# allwinner_d1_unofficial register map
File version: 0.1
Registers are 32-bit, read-write, reset 0x0 unless marked. A register's access mark holds for its fields unless they carry their own. Offsets are from the block's base; [hi:lo] are bit positions; {n}, {i} and the like mark numbered series.

## CLINT — Core-Local Interruptor
Base 0x14000000
0x00 msip range 0..1 — MSIP Register for hart 0
0x4000 mtimecmpl — MTIMECMPL Register for hart 0
0x4004 mtimecmph — MTIMECMPH Register for hart 0
0xBFF8 mtime 64-bit ro (reset mask 0xFFFFFFFF) — MTIME . REF: opensbi
0xC000 ssip range 0..1 — SSIP Register for hart 0
0xD000 stimecmpl — STIMECMPL Register for hart 0
0xD004 stimecmph — STIMECMPH Register for hart 0

## TIMER — Timer Module, includes timer0, timer1, watchdog and audio video synchronization
Base 0x02050000
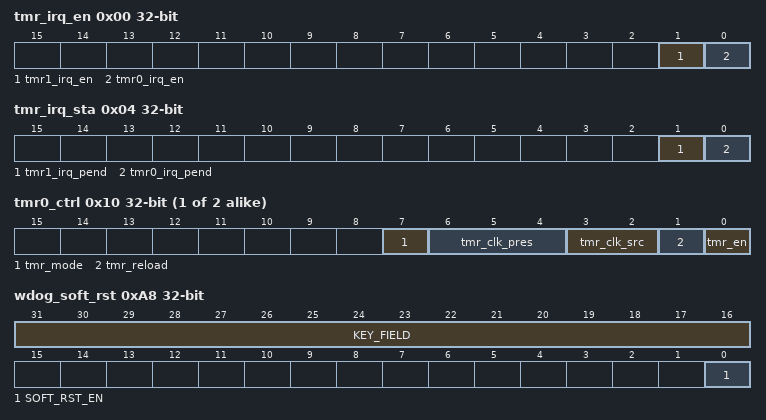
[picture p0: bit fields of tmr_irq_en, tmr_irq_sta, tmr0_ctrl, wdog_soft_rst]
0x00 tmr_irq_en — Timer IRQ Enable Register
  [1] tmr1_irq_en
    0=disabled; 1=enabled
  [0] tmr0_irq_en
    0=disabled; 1=enabled
0x04 tmr_irq_sta — Timer Status Register
  [1] tmr1_irq_pend
    0=no_effect; 1=pending (Indicates that the interval value of the timer 1 is reached. Write 1 to clear the pending status.)
  [0] tmr0_irq_pend
    0=no_effect; 1=pending (Indicates that the interval value of the timer 0 is reached. Write 1 to clear the pending status.)
{0x10+0x10*i} tmr{i}_ctrl (i=0..1) — Timer IRQ Enable Register
  [7] tmr_mode
    0=periodic; 1=single_counting
  [6:4] tmr_clk_pres
    0=P1; 1=P2; 2=P4; 3=P8; 4=P16; 5=P32; 6=P64; 7=P128
  [3:2] tmr_clk_src
    0=losc; 1=osc24_m
  [1] tmr_reload
    0=no_effect; 1=reload
  [0] tmr_en
    0=stop_pause; 1=start
{0x14+0x10*i} tmr{i}_intv_value (i=0..1) — Timer Interval Value Register
{0x18+0x10*i} tmr{i}_cur_value (i=0..1) — Timer Current Value Register
0xA0 wdog_irq_en — Watchdog IRQ Enable Register
  [0] wdog_irq_en
    0=disabled; 1=enabled
0xA4 wdog_irq_sta — Watchdog Status Register
  [0] wdog_irq_pend
    0=no_effect; 1=pending (Indicates that the interval value of the watchdog is reached.)
0xA8 wdog_soft_rst — Watchdog Software Reset Register
  [31:16] KEY_FIELD wo
  [0] SOFT_RST_EN — Soft Reset Enable
    0=Deassert; 1=Reset
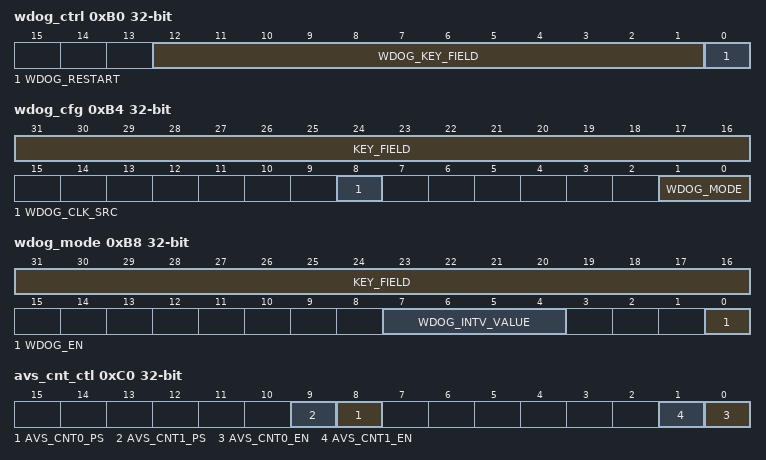
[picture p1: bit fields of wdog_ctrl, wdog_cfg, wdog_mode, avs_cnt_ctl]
0xB0 wdog_ctrl — Watchdog Control Register
  [12:1] WDOG_KEY_FIELD wo — Watchdog Key Field
  [0] WDOG_RESTART write-1-sets — Watchdog Restart
    0=no_effect; 1=restart
0xB4 wdog_cfg — Watchdog Configuration Register
  [31:16] KEY_FIELD wo
  [8] WDOG_CLK_SRC — Select the clock source for the watchdog.
    0=HOSC_32K; 1=LOSC_32K
  [1:0] WDOG_MODE — Configure the operating mode for the watchdog
    1=whold_system; 2=only_interrupt
0xB8 wdog_mode — Watchdog Mode Register
  [31:16] KEY_FIELD wo
  [7:4] WDOG_INTV_VALUE — Watchdog Interval Value
    0=C16000; 1=C32000; 2=C64000; 3=C96000; 4=C128000; 5=C160000; 6=C192000; 7=C256000; 8=C320000; 9=C384000; 10=C448000; 11=C512000
  [0] WDOG_EN — Watchdog Enable
    0=no_effect; 1=enable
0xBC wdog_output_cfg — Watchdog Output Configuration Register
  [11:0] WDOG_OUTPUT_CONFIG — Configure the valid time for the watchdog reset signal.
0xC0 avs_cnt_ctl — AVS Counter Control Register
  [n+8] AVS_CNT{n}_PS (n=0..1) — Audio Video Sync Counter Pause Control
    0=not_pause; 1=pause
  [n] AVS_CNT{n}_EN (n=0..1) — Audio Video Sync Counter Enable
    0=disabled; 1=enabled
0xC4 avs_cnt0 — AVS Counter 0 Register
0xC8 avs_cnt1 — AVS Counter 1 Register
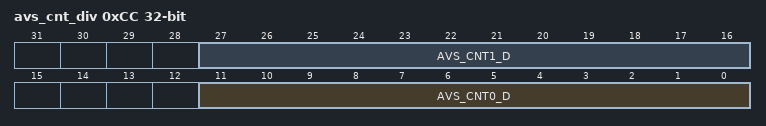
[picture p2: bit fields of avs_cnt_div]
0xCC avs_cnt_div — AVS Counter Divisor Register
  [16n+11:16n] AVS_CNT{n}_D (n=0..1) — The divisor factor of AVS

## HSTimer — High Speed Timer
Base 0x03008000
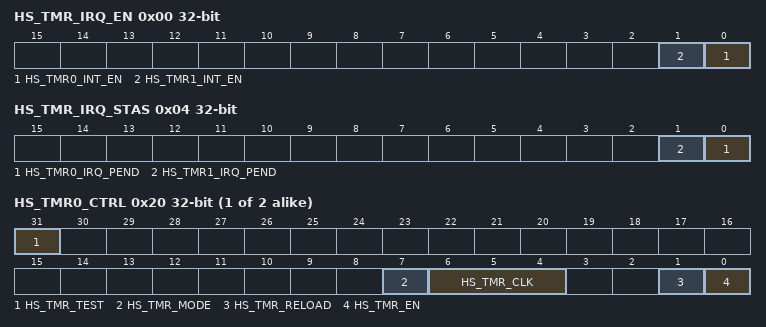
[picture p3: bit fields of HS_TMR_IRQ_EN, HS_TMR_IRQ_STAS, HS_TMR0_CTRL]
0x00 HS_TMR_IRQ_EN — HS Timer IRQ Enable Register
  [n] HS_TMR{n}_INT_EN (n=0..1) — HSTimer Interrupt Enable
    0=disabled; 1=enabled
0x04 HS_TMR_IRQ_STAS — HS Timer Status Register
  [n] HS_TMR{n}_IRQ_PEND (n=0..1) write-1-clears — HSTimer IRQ Pending
    0=no_effect; 1=pending
{0x20+0x20*i} HS_TMR{i}_CTRL (i=0..1) — HS Timer Control Register
  [31] HS_TMR_TEST — Select the operating mode for HSTimer
    0=Normal; 1=Test
  [7] HS_TMR_MODE — Select the timing mode for HSTimer
    0=periodic; 1=one_shot
  [6:4] HS_TMR_CLK — Select the pre-scale for the HSTimer clock sources
    0=P1; 1=P2; 2=P4; 3=P8; 4=P16
  [1] HS_TMR_RELOAD write-1-sets — HSTimer Reload
    0=no_effect; 1=reload
  [0] HS_TMR_EN — HSTimer Enable
    0=stop_pause; 1=start
{0x24+0x20*i} HS_TMR{i}_INTV_LO (i=0..1) — HS Timer Interval Value Low Register
{0x28+0x20*i} HS_TMR{i}_INTV_HI (i=0..1) — HS Timer Interval Value High Register
  [23:0] HS_TMR_INTV_VALUE_HI
{0x2C+0x20*i} HS_TMR{i}_CURNT_LO (i=0..1) — HS Timer Current Value Low Register
{0x30+0x20*i} HS_TMR{i}_CURNT_HI (i=0..1) — HS Timer Current Value High Register
  [23:0] HS_TMR_CUR_VALUE_HI
